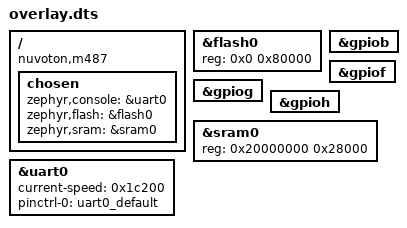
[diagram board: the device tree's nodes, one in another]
/ {
	compatible = "nuvoton,m487", "nuvoton,pfm-m487";
	chosen {
		zephyr,console = &uart0;
		zephyr,flash = &flash0;
		zephyr,sram = &sram0;
	};
};
&flash0{
	reg = < 0x0 0x80000 >;
};
&gpiob{
	status = "okay";
};
&gpiof{
	status = "okay";
};
&gpiog{
	status = "okay";
};
&gpioh{
	status = "okay";
};
&sram0{
	reg = < 0x20000000 0x28000 >;
};
&uart0{
	status = "okay";
	current-speed = < 0x1c200 >;
	pinctrl-0 = < &uart0_default >;
	pinctrl-names = "default";
};
